# ATA5781 device description
Architecture: AVR8; Family: megaAVR
Registers are 8-bit, access not given, no defined reset value unless marked. A register's access mark holds for its fields unless they carry their own. Offsets are from the block's base; [hi:lo] are bit positions.

## RXDSP
Instances: RXDSP 0x00
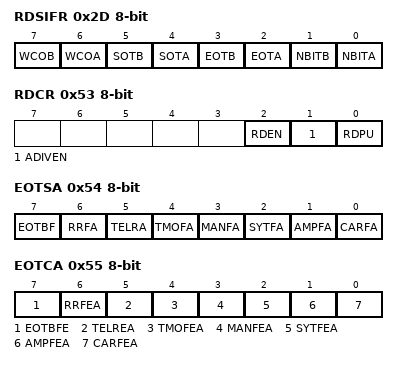
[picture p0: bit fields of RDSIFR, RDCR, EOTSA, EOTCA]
0x2D RDSIFR — Rx DSP status interrupt flag register
  [7] WCOB — Wake Conditions Ok on path B
  [6] WCOA — Wake Conditions Ok on path A
  [5] SOTB — Start Of Telegram on path B
  [4] SOTA — Start Of Telegram on path A
  [3] EOTB — End Of Telegram on path B
  [2] EOTA — End Of Telegram on path A
  [1] NBITB — New Bit on Rx path B
  [0] NBITA — New Bit on Rx path A
0x53 RDCR — Rx DSP control register
  [2] RDEN — Rx DSP enable
  [1] ADIVEN — Divided ADC clock enable
  [0] RDPU — Rx DSP Power Up
0x54 EOTSA — End Of Telegram Status on path A
  [7] EOTBF — End Of Telegram on path B Flag
  [6] RRFA — RSSI Range Fail on path A
  [5] TELRA — Telegram Length Reached on path A
  [4] TMOFA — Time-Out Fail on path A
  [3] MANFA — MANchester coding Failed on path A
  [2] SYTFA — SYmbol Timing check Failed on path A
  [1] AMPFA — AMPlitude Failed on path A
  [0] CARFA — CARrier check Failed on path A
0x55 EOTCA — End Of Telegram Conditions for path A
  [7] EOTBFE — End Of Telegram on path B Fail Enable
  [6] RRFEA — RSSI Range Fail Enable on path A
  [5] TELREA — Telegram Length Reached Enable on path A
  [4] TMOFEA — Time-Out Fail Enable on path A
  [3] MANFEA — MANchester Coding Failed Enable for path A
  [2] SYTFEA — SYmbol Timing check Failed Enable for path A
  [1] AMPFEA — AMPlitude Failed Enable for path A
  [0] CARFEA — CARrier check Failed Enable for path A
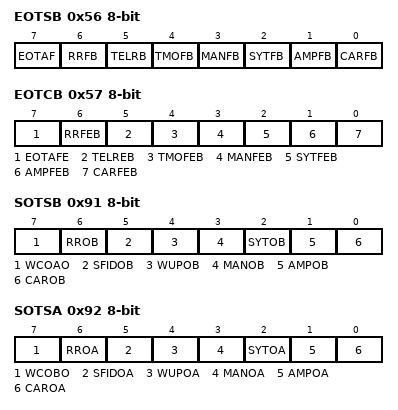
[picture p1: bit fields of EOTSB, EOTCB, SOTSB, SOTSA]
0x56 EOTSB — End Of Telegram Status on path B
  [7] EOTAF — End Of Telegram on path A Flag
  [6] RRFB — RSSI Range Fail on path B
  [5] TELRB — Telegram Length Reached on path B
  [4] TMOFB — Time-Out Fail on path B
  [3] MANFB — MANchester coding Failed on path B
  [2] SYTFB — SYmbol Timing check Failed on path B
  [1] AMPFB — AMPlitude Failed on path B
  [0] CARFB — CARrier check Failed on path B
0x57 EOTCB — End Of Telegram Conditions for path B
  [7] EOTAFE — End Of Telegram on path B Fail Enable
  [6] RRFEB — RSSI Range Fail Enable on path B
  [5] TELREB — Telegram Length Reached Enable on path B
  [4] TMOFEB — Time-Out Fail Enable on path B
  [3] MANFEB — MANchester Coding Failed Enable for path B
  [2] SYTFEB — SYmbol Timing check Failed Enable for path B
  [1] AMPFEB — AMPlitude Failed Enable for path B
  [0] CARFEB — CARrier check Failed Enable for path B
0x91 SOTSB — Start Of Telegram Status for path B
  [7] WCOAO — Wake Check Ok on path A Ok
  [6] RROB — RSSI Range Ok on Path B
  [5] SFIDOB — Start of Frame IDentifier matched on path B
  [4] WUPOB — Wake Up Pattern matched on path B
  [3] MANOB — Manchester Coding Ok on path B
  [2] SYTOB — Symbol Timing Ok on path B
  [1] AMPOB — AMPlitude Ok on path B
  [0] CAROB — CARrier check Ok on path B
0x92 SOTSA — Start Of Telegram Status for path A
  [7] WCOBO — Wake Check Ok on path B Ok
  [6] RROA — RSSI Range Ok on Path A
  [5] SFIDOA — Start of Frame IDentifier matched on path A
  [4] WUPOA — Wake Up Pattern matched on path A
  [3] MANOA — Manchester Coding Ok on path A
  [2] SYTOA — Symbol Timing Ok on path A
  [1] AMPOA — AMPlitude Ok on path A
  [0] CAROA — CARrier check Ok on path A
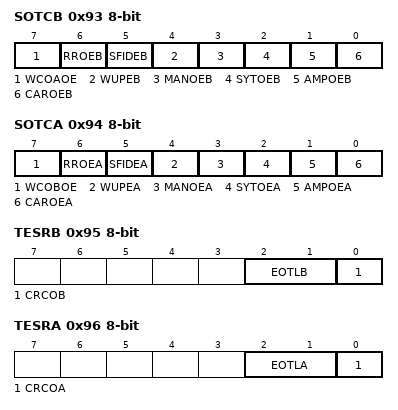
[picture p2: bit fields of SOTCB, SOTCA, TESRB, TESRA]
0x93 SOTCB — Start Of Telegram Conditions for path B
  [7] WCOAOE — Wake Check OK from path A Ok Enable
  [6] RROEB — RSSI Range OK Enable for path B
  [5] SFIDEB — Start of Frame IDentifier match Enabled for path B
  [4] WUPEB — Wake Up Pattern match Enabled for path B
  [3] MANOEB — Manchester Coding Ok Enabled for path B
  [2] SYTOEB — Symbol Timing Ok Enabled for path B
  [1] AMPOEB — AMPlitude Ok Enabled for path B
  [0] CAROEB — CARrier check Ok Enabled for path B
0x94 SOTCA — Start Of Telegram Conditions for path A
  [7] WCOBOE — Wake Check OK from path B Ok Enable
  [6] RROEA — RSSI Range OK Enable for path A
  [5] SFIDEA — Start of Frame IDentifier match Enabled for path A
  [4] WUPEA — Wake Up Pattern match Enabled for path A
  [3] MANOEA — Manchester Coding Ok Enabled for path A
  [2] SYTOEA — Symbol Timing Ok Enabled for path A
  [1] AMPOEA — AMPlitude Ok Enabled for path A
  [0] CAROEA — CARrier check Ok Enabled for path A
0x95 TESRB — Telegram Status Register on Path B
  [2:1] EOTLB — End of Telegram Location on path B
    0=No EOT; 1=Before WCO; 2=Between WCO and SOT; 3=After SOT
  [0] CRCOB — Cyclic Redundancy Check Ok on path B
0x96 TESRA — Telegram Status Register on Path A
  [2:1] EOTLA — End of Telegram Location on path A
    0=No EOT; 1=Before WCO; 2=Between WCO and SOT; 3=After SOT
  [0] CRCOA — Cyclic Redundancy Check Ok on path A
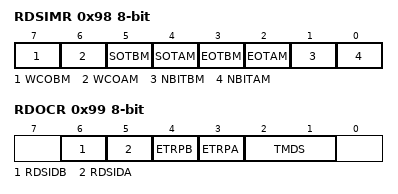
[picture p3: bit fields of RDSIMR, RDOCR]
0x98 RDSIMR — Rx DSP status interrupt mask register
  [7] WCOBM — Wake Conditions Ok on path B interrupt mask register
  [6] WCOAM — Wake Conditions Ok on path A interrupt mask register
  [5] SOTBM — Start Of Telegram on Rx path B interrupt mask register
  [4] SOTAM — Start Of Telegram on Rx path A interrupt mask register
  [3] EOTBM — End Of Telegram on Rx path B interrupt mask register
  [2] EOTAM — End Of Telegram on Rx path A interrupt mask register
  [1] NBITBM — New bit on Rx path B interrupt mask register
  [0] NBITAM — New bit on Rx path A interrupt mask register
0x99 RDOCR — Rx DSP output control
  [6] RDSIDB — Rx DSP Start bit Is Data for path B
  [5] RDSIDA — Rx DSP Start bit Is Data for path A
  [4] ETRPB — Enable Transparent Path B
  [3] ETRPA — Enable Transparent Path A
  [2:1] TMDS — Transparent Mode Data Select
